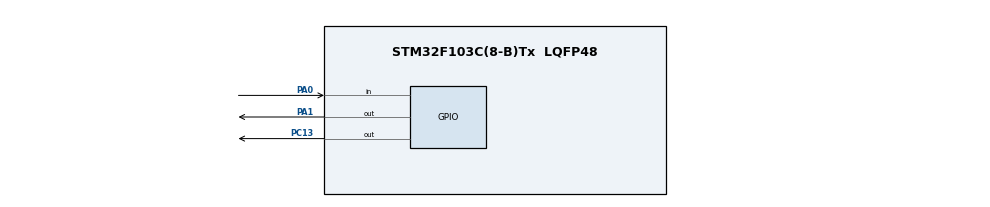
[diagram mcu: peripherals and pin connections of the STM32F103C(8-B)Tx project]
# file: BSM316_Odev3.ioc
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Mcu.Family=STM32F1
Mcu.Name=STM32F103C(8-B)Tx
Mcu.Package=LQFP48
NVIC.PriorityGroup=NVIC_PRIORITYGROUP_4
NVIC.TIM2_IRQn=true\:0\:0\:false\:false\:true\:true\:true\:true
PA0-WKUP.GPIO_PuPd=GPIO_PULLUP
PA0-WKUP.Signal=GPIO_Input
PA1.Signal=GPIO_Output
PC13-TAMPER-RTC.Signal=GPIO_Output
ProjectManager.HeapSize=0x200
ProjectManager.StackSize=0x400
ProjectManager.TargetToolchain=Makefile
RCC.APB1Freq_Value=8000000
RCC.APB2Freq_Value=8000000
TIM2.Prescaler=7999
VP_SYS_VS_ND.Mode=No_Debug
VP_TIM2_VS_ClockSourceINT.Mode=Internal
board=custom

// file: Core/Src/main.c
/* USER CODE BEGIN Header */
/**
  ******************************************************************************
  * @file           : main.c
  * @brief          : Main program body
  ******************************************************************************
  * @attention
  *
  * Copyright (c) 2026 STMicroelectronics.
  * All rights reserved.
  *
  * This software is licensed under terms that can be found in the LICENSE file
  * in the root directory of this software component.
  * If no LICENSE file comes with this software, it is provided AS-IS.
  *
  ******************************************************************************
  */
/* USER CODE END Header */
#include "main.h"

/* USER CODE BEGIN PD */
#define FLASH_ADDR 0x0800FC00
/* USER CODE END PD */

TIM_HandleTypeDef htim2;

/* USER CODE BEGIN PV */
uint32_t blink_count = 4;
uint32_t current_blink = 0;
uint8_t is_blinking = 1;
uint8_t wait_seconds = 0;
/* USER CODE END PV */

void SystemClock_Config(void);
static void MX_GPIO_Init(void);
static void MX_TIM2_Init(void);
/* USER CODE BEGIN PFP */
void Write_Flash(uint32_t data);
uint32_t Read_Flash(void);
/* USER CODE END PFP */

/* USER CODE BEGIN 0 */
void Write_Flash(uint32_t data) {
    HAL_FLASH_Unlock();
    FLASH_EraseInitTypeDef EraseInitStruct;
    uint32_t PageError;
    EraseInitStruct.TypeErase = FLASH_TYPEERASE_PAGES;
    EraseInitStruct.PageAddress = FLASH_ADDR;
    EraseInitStruct.NbPages = 1;
    HAL_FLASHEx_Erase(&EraseInitStruct, &PageError);
    HAL_FLASH_Program(FLASH_TYPEPROGRAM_WORD, FLASH_ADDR, data);
    HAL_FLASH_Lock();
}

uint32_t Read_Flash(void) {
    return *(__IO uint32_t*)FLASH_ADDR;
}
/* USER CODE END 0 */

int main(void)
{

  /* MCU Configuration--------------------------------------------------------*/

  /* Reset of all peripherals, Initializes the Flash interface and the Systick. */
  HAL_Init();

  /* Configure the system clock */
  SystemClock_Config();

  /* Initialize all configured peripherals */
  MX_GPIO_Init();
  MX_TIM2_Init();
  /* USER CODE BEGIN 2 */

  HAL_GPIO_WritePin(GPIOC, GPIO_PIN_13, GPIO_PIN_SET);

  uint32_t start_time = HAL_GetTick();
  uint8_t factory_reset = 0;

  if (HAL_GPIO_ReadPin(GPIOA, GPIO_PIN_0) == GPIO_PIN_RESET) {
      while (HAL_GPIO_ReadPin(GPIOA, GPIO_PIN_0) == GPIO_PIN_RESET) {
          if (HAL_GetTick() - start_time >= 3000) {
              factory_reset = 1;
          }
      }
  }

  blink_count = Read_Flash();
  if (blink_count == 0xFFFFFFFF || blink_count > 7 || blink_count < 4) {
      blink_count = 4;
      Write_Flash(blink_count);
  }

  if (factory_reset) {
      blink_count = 4;
      Write_Flash(blink_count);
  }

  HAL_TIM_Base_Start_IT(&htim2);

  /* USER CODE END 2 */

  /* Infinite loop */
  /* USER CODE BEGIN WHILE */
  uint8_t prev_button_state = 1;
  while (1)
  {
      uint8_t current_button_state = HAL_GPIO_ReadPin(GPIOA, GPIO_PIN_0) == GPIO_PIN_RESET ? 0 : 1;

      if (current_button_state == 0 && prev_button_state == 1) {
          HAL_Delay(50);
          if (HAL_GPIO_ReadPin(GPIOA, GPIO_PIN_0) == GPIO_PIN_RESET) {
              if (blink_count < 7) {
                  blink_count++;
              } else {
                  blink_count = 4;
              }
              Write_Flash(blink_count);

              __disable_irq();
              current_blink = 0;
              is_blinking = 1;
              wait_seconds = 0;
              HAL_GPIO_WritePin(GPIOC, GPIO_PIN_13, GPIO_PIN_SET);
              __HAL_TIM_SET_COUNTER(&htim2, 0);
              __enable_irq();

              while(HAL_GPIO_ReadPin(GPIOA, GPIO_PIN_0) == GPIO_PIN_RESET) {

              }
              HAL_Delay(50);
          }
      }
      prev_button_state = current_button_state;
    /* USER CODE END WHILE */

  }
}

void SystemClock_Config(void)
{
  RCC_OscInitTypeDef RCC_OscInitStruct = {0};
  RCC_ClkInitTypeDef RCC_ClkInitStruct = {0};

  /** Initializes the RCC Oscillators according to the specified parameters
  * in the RCC_OscInitTypeDef structure.
  */
  RCC_OscInitStruct.OscillatorType = RCC_OSCILLATORTYPE_HSI;
  RCC_OscInitStruct.HSIState = RCC_HSI_ON;
  RCC_OscInitStruct.HSICalibrationValue = RCC_HSICALIBRATION_DEFAULT;
  RCC_OscInitStruct.PLL.PLLState = RCC_PLL_NONE;
  if (HAL_RCC_OscConfig(&RCC_OscInitStruct) != HAL_OK)
  {
    Error_Handler();
  }

  /** Initializes the CPU, AHB and APB buses clocks
  */
  RCC_ClkInitStruct.ClockType = RCC_CLOCKTYPE_HCLK|RCC_CLOCKTYPE_SYSCLK
                              |RCC_CLOCKTYPE_PCLK1|RCC_CLOCKTYPE_PCLK2;
  RCC_ClkInitStruct.SYSCLKSource = RCC_SYSCLKSOURCE_HSI;
  RCC_ClkInitStruct.AHBCLKDivider = RCC_SYSCLK_DIV1;
  RCC_ClkInitStruct.APB1CLKDivider = RCC_HCLK_DIV1;
  RCC_ClkInitStruct.APB2CLKDivider = RCC_HCLK_DIV1;

  if (HAL_RCC_ClockConfig(&RCC_ClkInitStruct, FLASH_LATENCY_0) != HAL_OK)
  {
    Error_Handler();
  }
}

static void MX_TIM2_Init(void)
{

  TIM_ClockConfigTypeDef sClockSourceConfig = {0};
  TIM_MasterConfigTypeDef sMasterConfig = {0};

  htim2.Instance = TIM2;
  htim2.Init.Prescaler = 7999;
  htim2.Init.CounterMode = TIM_COUNTERMODE_UP;
  htim2.Init.Period = 999;
  htim2.Init.ClockDivision = TIM_CLOCKDIVISION_DIV1;
  htim2.Init.AutoReloadPreload = TIM_AUTORELOAD_PRELOAD_DISABLE;
  if (HAL_TIM_Base_Init(&htim2) != HAL_OK)
  {
    Error_Handler();
  }
  sClockSourceConfig.ClockSource = TIM_CLOCKSOURCE_INTERNAL;
  if (HAL_TIM_ConfigClockSource(&htim2, &sClockSourceConfig) != HAL_OK)
  {
    Error_Handler();
  }
  sMasterConfig.MasterOutputTrigger = TIM_TRGO_RESET;
  sMasterConfig.MasterSlaveMode = TIM_MASTERSLAVEMODE_DISABLE;
  if (HAL_TIMEx_MasterConfigSynchronization(&htim2, &sMasterConfig) != HAL_OK)
  {
    Error_Handler();
  }

}

static void MX_GPIO_Init(void)
{
  GPIO_InitTypeDef GPIO_InitStruct = {0};

  /* GPIO Ports Clock Enable */
  __HAL_RCC_GPIOC_CLK_ENABLE();
  __HAL_RCC_GPIOA_CLK_ENABLE();

  /*Configure GPIO pin Output Level */
  HAL_GPIO_WritePin(GPIOC, GPIO_PIN_13, GPIO_PIN_RESET);

  /*Configure GPIO pin Output Level */
  HAL_GPIO_WritePin(GPIOA, GPIO_PIN_1, GPIO_PIN_RESET);

  /*Configure GPIO pin : PC13 */
  GPIO_InitStruct.Pin = GPIO_PIN_13;
  GPIO_InitStruct.Mode = GPIO_MODE_OUTPUT_PP;
  GPIO_InitStruct.Pull = GPIO_NOPULL;
  GPIO_InitStruct.Speed = GPIO_SPEED_FREQ_LOW;
  HAL_GPIO_Init(GPIOC, &GPIO_InitStruct);

  /*Configure GPIO pin : PA0 */
  GPIO_InitStruct.Pin = GPIO_PIN_0;
  GPIO_InitStruct.Mode = GPIO_MODE_INPUT;
  GPIO_InitStruct.Pull = GPIO_PULLUP;
  HAL_GPIO_Init(GPIOA, &GPIO_InitStruct);

  /*Configure GPIO pin : PA1 */
  GPIO_InitStruct.Pin = GPIO_PIN_1;
  GPIO_InitStruct.Mode = GPIO_MODE_OUTPUT_PP;
  GPIO_InitStruct.Pull = GPIO_NOPULL;
  GPIO_InitStruct.Speed = GPIO_SPEED_FREQ_LOW;
  HAL_GPIO_Init(GPIOA, &GPIO_InitStruct);

}

/* USER CODE BEGIN 4 */
void HAL_TIM_PeriodElapsedCallback(TIM_HandleTypeDef *htim) {
    if (htim->Instance == TIM2) {
        if (is_blinking) {
            HAL_GPIO_TogglePin(GPIOC, GPIO_PIN_13);
            if (HAL_GPIO_ReadPin(GPIOC, GPIO_PIN_13) == GPIO_PIN_SET) {
                current_blink++;
                if (current_blink >= blink_count) {
                    is_blinking = 0;
                    current_blink = 0;
                    wait_seconds = 5;
                }
            }
        } else {
            HAL_GPIO_WritePin(GPIOC, GPIO_PIN_13, GPIO_PIN_SET);
            if (wait_seconds > 0) {
                wait_seconds--;
            }
            if (wait_seconds == 0) {
                is_blinking = 1;
            }
        }
    }
}
/* USER CODE END 4 */

void Error_Handler(void)
{
  __disable_irq();
  while (1)
  {
  }
}
